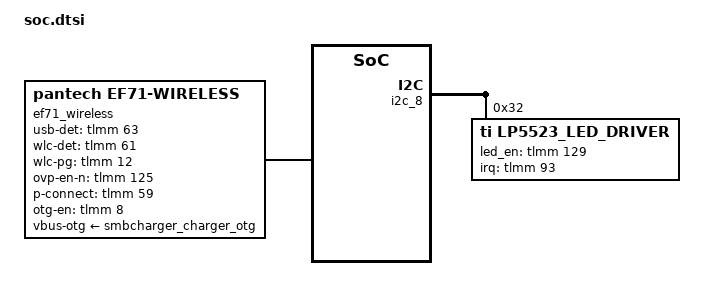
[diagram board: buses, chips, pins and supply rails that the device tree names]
// SPDX-License-Identifier: GPL-2.0-only

&soc {
	i2c_8: i2c@7af8000 { /* BLSP2 QUP4 */
		compatible = "qcom,i2c-msm-v2";
		#address-cells = <1>;
		#size-cells = <0>;
		reg-names = "qup_phys_addr";
		reg = <0x7af8000 0x600>;
		interrupt-names = "qup_irq";
		interrupts = <0 302 IRQ_TYPE_LEVEL_HIGH>;
		qcom,clk-freq-out = <400000>;
		qcom,clk-freq-in  = <19200000>;
		clock-names = "iface_clk", "core_clk";
		clocks = <&gcc GCC_BLSP2_AHB_CLK>,
			<&gcc GCC_BLSP2_QUP4_I2C_APPS_CLK>;

		pinctrl-names = "i2c_active", "i2c_sleep";
		pinctrl-0 = <&i2c_8_active>;
		pinctrl-1 = <&i2c_8_sleep>;
		qcom,noise-rjct-scl = <0>;
		qcom,noise-rjct-sda = <0>;
		qcom,master-id = <84>;
		dmas = <&dma_blsp2 10 64 0x20000020 0x20>,
			<&dma_blsp2 11 32 0x20000020 0x20>;
		dma-names = "tx", "rx";
		status = "disabled";
	};
};

/* i2c-msm-v2 takes the bus number from the alias */
&{/aliases} {
	i2c8 = &i2c_8;
};

&i2c_8 {
	status = "ok";

	/* Notification and key backlight LEDs */
	lp5523_led_driver@32 {
		compatible = "ti,lp5523_led_driver";
		reg = <0x32>;
		interrupt-parent = <&tlmm>;
		interrupts = <93 0x2008>;
		lp5523,clock_mode = <1>;
		lp5523,led_en_gpio = <&tlmm 129 0x00>;
		lp5523,max_chan = <9>;
		lp5523,led_current = <40>;
		lp5523,max_current = <250>;
	};
};

/*
 * The PN548 sits where the MTP has its NQ controller, on the same pins
 * and clock: the qcom,nq-nci node and driver serve it, and give the
 * /dev/nq-nci the NFC HAL opens.
 */

/*
 * Wireless charging: the BQ51221 receiver feeds the PMI8950 DCIN, behind
 * the MAX14731 input switch. qpnp-smbcharger charges from it as its "dc"
 * supply.
 */
&soc {
	ef71_wireless {
		compatible = "pantech,ef71-wireless";
		usb-det-gpios = <&tlmm 63 0>;
		wlc-det-gpios = <&tlmm 61 0>;
		wlc-pg-gpios = <&tlmm 12 0>;
		ovp-en-n-gpios = <&tlmm 125 0>;
		p-connect-gpios = <&tlmm 59 0>;
		otg-en-gpios = <&tlmm 8 0>;
		vbus-otg-supply = <&smbcharger_charger_otg>;
		pinctrl-names = "default";
		pinctrl-0 = <&ef71_wlc_det_default &ef71_wlc_ctrl_default>;
	};
};
